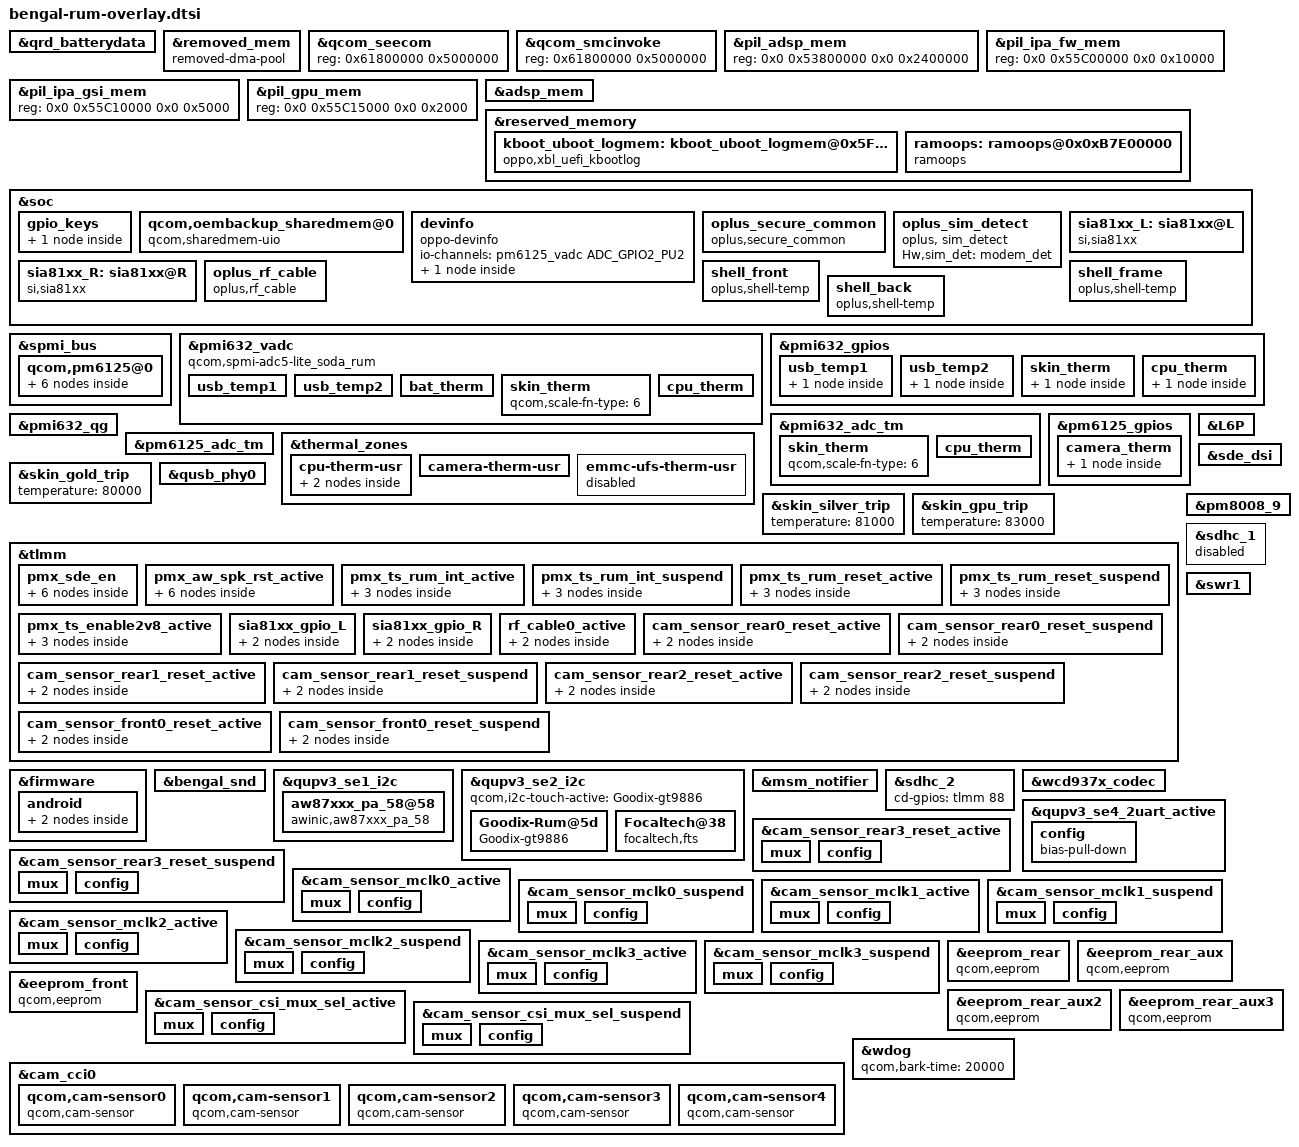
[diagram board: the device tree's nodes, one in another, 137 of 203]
/* *****************
the up part file change like:
delete note  and status = "disabled" to "ok"  add here also, other will meet can't boot issue or compile error issue
**************************/
#include "../../qcom/bengal-qrd.dtsi"
#include "nfc/rum-nfc-sn100t.dtsi"
#include "dsi-panel-oplus20211-s6e8fc1-samsung-fhd-video.dtsi"
#include "fingerprint/bengal-rum-fingerprint-overlay.dtsi"
//bengal.dtsi

&qrd_batterydata {
    /delete-node/ qcom,ATL466271_3300mAh;
    #include "oplus_battery_4000mah_100k_pmi632_TWS_Atl.dtsi"
};
//#ifdef OPLUS_FEATURE_FINGERPRINT
&removed_mem {
	compatible = "removed-dma-pool";
	no-map;
	reg = <0x0 0x60000000 0x0 0x6800000>;
};
&qcom_seecom {
	/delete-property/ reg;
	reg = <0x61800000 0x5000000>;
};
&qcom_smcinvoke {
	/delete-property/ reg;
	reg = <0x61800000 0x5000000>;
};
//#endif /*OPLUS_FEATURE_FINGERPRINT*/

&pil_adsp_mem {
	/delete-property/ reg;
	reg = <0x0 0x53800000 0x0 0x2400000>;
};

&pil_ipa_fw_mem {
	/delete-property/ reg;
	reg = <0x0 0x55C00000 0x0 0x10000>;
};

&pil_ipa_gsi_mem {
	/delete-property/ reg;
	reg = <0x0 0x55C10000 0x0 0x5000>;
};

&pil_gpu_mem {
	/delete-property/ reg;
	reg = <0x0 0x55C15000 0x0 0x2000>;
};

&adsp_mem {
	/delete-property/ reusable;
};

// xbl_uefi_mem address get from boot_images Core.dsc.inc file: PcdEmbeddedFdBaseAddress + SERIAL_BUFFER_OFFSET,0x5FC00000+0x3F7000
// kernel boot log: 0x5FC00000~ 0x5FFF7000
&reserved_memory {
	kboot_uboot_logmem: kboot_uboot_logmem@0x5FC00000 {
		reg = <0x0 0x5FC00000 0x0 0x3FF000>;
		compatible = "oppo,xbl_uefi_kbootlog";
		xbluefi-offset = <0x3F7000>;
		no-map;
	};

	ramoops: ramoops@0x0xB7E00000 {
		compatible = "ramoops";
		reg = <0 0xB7E00000 0 0x00400000>;
		record-size =  <0x40000>; //256x1024
		console-size = <0x40000>;
		ftrace-size =  <0x40000>;
		pmsg-size=         <0x200000>;
		devinfo-size=  <0x01000>;
		ecc-size=          <0x0>;
	};
};
//bengal-qrd.dtsi
&soc {
	gpio_keys {
		vol_up {
			/delete-property/ label;
			label = "volume_down";
			/delete-property/ linux,code;
			linux,code = <KEY_VOLUMEDOWN>;
		};
	};

	//#ifdef FEATURE_OPPO_NV_BACKUP
	//add for creating a shared memory with uio for nv backup and restore
	qcom,oembackup_sharedmem@0 {
		compatible = "qcom,sharedmem-uio";
		reg = <0x0 0x00100000>;
		reg-names = "oembackup";
		qcom,client-id = <0x00000004>;
		qcom,guard-memory;
		qcom,vm-nav-path;
	};
	//#endif /* FEATURE_OPPO_NV_BACKUP */

	devinfo {
		compatible = "oppo-devinfo";

		io-channels= <&pm6125_vadc ADC_GPIO2_PU2>;
		io-channel-names= "vph_pwr_voltage_sub";

		main-sub {
			compatible = "hw-match, main-sub";
			use_pmic_adc;
			adc_ranges = <  0 79
					80 150
					151 849
					850 1050
					1051 1900>;
			aboard-patterns = <1 3 3 1 1 1>;

			/*main board*/
			match-projects = <20011 20211 20212 20213 20214 20215>;
		};
	};
    // #ifdef OPLUS_FEATURE_SECURITY_COMMON
    oplus_secure_common {
        compatible = "oplus,secure_common";
    };
    //#endif /* OPLUS_FEATURE_SECURITY_COMMON */

	//#ifdef OPLUS_FEATRUE_SIM_HOLDER_DETECT
	oplus_sim_detect {
		compatible = "oplus, sim_detect";
		Hw,sim_det = "modem_det";
	};
	//#endif /* OPLUS_FEATRUE_SIM_HOLDER_DETECT */

	//#ifdef OPLUS_ARCH_EXTENDS
	sia81xx_L: sia81xx@L {
			compatible = "si,sia81xx";
			si,sia81xx_type = "sia8109";
			si,sia81xx_reset = <&tlmm 98 0x00>;
			si,sia81xx_owi = <&tlmm 98 0x00>;
			pinctrl-names = "sia81xx_gpio";
			pinctrl-0 = <&sia81xx_gpio_L>;

			si,sia81xx_disable_pin = <1>;

			/* the same value share a same task
			 * valid value range : 0 ~ 7 */
			timer_task_hdl = <0>;

			channel_num = <0>;
			owi_mode = <6>;
			en_x_filter = <1>;
			en_dynamic_updata_vdd = <1>;
			dynamic_updata_vdd_port = <0xb030>;
	};

	sia81xx_R: sia81xx@R {
			compatible = "si,sia81xx";
			si,sia81xx_type = "sia8109";
			si,sia81xx_reset = <&tlmm 107 0x00>;
			si,sia81xx_owi = <&tlmm 107 0x00>;
			pinctrl-names = "sia81xx_gpio";
			pinctrl-0 = <&sia81xx_gpio_R>;

			si,sia81xx_disable_pin = <1>;

			/* the same value share a same task
			 * valid value range : 0 ~ 7 */
			timer_task_hdl = <0>;

			channel_num = <1>;
			owi_mode = <6>;
			en_x_filter = <0>;
			en_dynamic_updata_vdd = <1>;
			dynamic_updata_vdd_port = <0xb030>;
	};
	//#endif /* OPLUS_ARCH_EXTENDS */

	oplus_rf_cable {
		compatible = "oplus,rf_cable";
		interrupt-parent = <&tlmm>;
		rf_cable_support_num = <1>;
		rf,cable0-gpio = <&tlmm 106 0>;
		rf,cable-support-timer = <0>;
		pinctrl-names = "rf_cable_active";
		pinctrl-0 = <&rf_cable0_active>;
	};
	
	
	//#ifdef OPLUS_FEATURE_THERMAL_HORAE
	shell_front {
		compatible = "oplus,shell-temp";
	};

	shell_frame {
		compatible = "oplus,shell-temp";
	};

	shell_back {
		compatible = "oplus,shell-temp";
	};
	//#endif /* OPLUS_FEATURE_THERMAL_HORAE */
};
&spmi_bus {
	qcom,pm6125@0 {
		qcom,power-on@800 {
			qcom,pmicwd;
			qcom,pon_2 {
				qcom,pon-type = <1>;
				qcom,pull-up = <1>;
				linux,code = <KEY_VOLUMEUP>;
			};
		};
		pm6125_vadc: vadc@3100 {
			compatible = "qcom,spmi-adc5_soda_rum";
		};
    };
};
		&pmi632_vadc {
			compatible = "qcom,spmi-adc5-lite_soda_rum";
			pinctrl-0 = <&usb_temp1_default &usb_temp2_default &skin_therm_default &cpu_therm_default>;
			usb_temp1 {
				reg = <ADC_GPIO1_PU2>;
				label = "usb_temp1";
				qcom,ratiometric;
				qcom,hw-settle-time = <200>;
				qcom,pre-scaling = <1 1>;
				qcom,scale-fn-type = <ADC_SCALE_HW_CALIB_DEFAULT>;
			};
			usb_temp2 {
				reg = <ADC_GPIO3_PU2>;
				label = "usb_temp2";
				qcom,ratiometric;
				qcom,hw-settle-time = <200>;
				qcom,pre-scaling = <1 1>;
				qcom,scale-fn-type = <ADC_SCALE_HW_CALIB_DEFAULT>;
			};
			bat_therm {
				reg = <ADC_BAT_THERM_PU1>;
				label = "bat_therm";
				qcom,ratiometric;
				qcom,hw-settle-time = <200>;
				qcom,pre-scaling = <1 1>;
				qcom,lut-index = <3>;
			};
			skin_therm {
				//#ifdef ODM_HQ_EDIT
				qcom,scale-fn-type = <6>;
			};

			//#ifdef ODM_HQ_EDIT
			cpu_therm {
				reg = <ADC_AMUX_THM1_PU2>;
				label = "cpu_therm";
				qcom,ratiometric;
				qcom,hw-settle-time = <200>;
				qcom,pre-scaling = <1 1>;
			};
		};
		&pmi632_gpios {
			usb_temp1 {
				usb_temp1_default: usb_temp1_default {
					pins = "gpio1";
					bias-high-impedance;
				};
			};
			usb_temp2 {
				usb_temp2_default: usb_temp2_default {
					pins = "gpio4";
					bias-high-impedance;
				};
			};
			skin_therm {
				skin_therm_default: skin_therm_default {
					pins = "gpio3";
					bias-high-impedance;
				};
			};
			//#ifdef ODM_HQ_EDIT
			cpu_therm {
				cpu_therm_default: cpu_therm_default {
					pins = "gpio5";
					bias-high-impedance;
				};
			};
		};
		&pmi632_qg {
			io-channels = <&pmi632_vadc ADC_BAT_THERM_PU1>,
				<&pmi632_vadc ADC_PARALLEL_ISENSE>,
				<&pmi632_vadc ADC_BAT_ID_PU2>;
			io-channel-names = "batt-therm",
						"parallel_isense",
						"batt-id";
			qcom,qg-iterm-ma = <450>;
			qcom,s3-entry-ibat-ua = <20000>;
			qcom,s3-exit-ibat-ua = <38000>;
			qcom,vbatt-cutoff-mv = <3390>;
			qcom,fvss-enable;
			qcom,project-index = <1>;// soda = 0; rum = 1; coco = 2
			qcom,enable-qpnp-qg;
		};

&pmi632_adc_tm {
	io-channels = <&pmi632_vadc ADC_GPIO2_PU2>,
			<&pmi632_vadc ADC_AMUX_THM1_PU2>;

	/* Channel nodes */
	skin_therm {
		//#ifdef ODM_HQ_EDIT
		qcom,scale-fn-type = <6>;
		/*#endif*/
	};

	//#ifdef ODM_HQ_EDIT
	cpu_therm {
		reg = <ADC_AMUX_THM1_PU2>;
		qcom,ratiometric;
		qcom,hw-settle-time = <200>;
	};
};

&pm6125_vadc {
	pinctrl-0 = <&camera_therm_default &emmc_therm_default>;
	camera_flash_therm {
		reg = <ADC_GPIO1_PU2>;
		label = "camera_flash_therm";
		qcom,ratiometric;
		qcom,hw-settle-time = <200>;
		qcom,pre-scaling = <1 1>;
		qcom,scale-fn-type = <6>;
	};
};

&pm6125_gpios {
	camera_therm {
		camera_therm_default: camera_therm_default {
			pins = "gpio3";
			bias-high-impedance;
		};
	};
};

&spmi_bus {
	qcom,pm6125@0 {
		pm6125_adc_tm_iio: adc_tm@3400 {
			compatible = "qcom,adc-tm5-iio";
			reg = <0x3400 0x100>;
			#thermal-sensor-cells = <1>;
			#address-cells = <1>;
			#size-cells = <0>;
			io-channels = <&pm6125_vadc ADC_GPIO1_PU2>,
					<&pm6125_vadc ADC_GPIO2_PU2>;

			camera_flash_therm {
				reg = <ADC_GPIO1_PU2>;
				qcom,ratiometric;
				qcom,hw-settle-time = <200>;
			};
		};
	};
};

&pm6125_adc_tm {
	io-channels = <&pm6125_vadc ADC_AMUX_THM1_PU2>,
			<&pm6125_vadc ADC_AMUX_THM2_PU2>,
			<&pm6125_vadc ADC_XO_THERM_PU2>;
};

&thermal_zones {
	//#ifdef ODM_HQ_EDIT
	cpu-therm-usr {
		polling-delay-passive = <0>;
		polling-delay = <0>;
		thermal-governor = "user_space";
		thermal-sensors = <&pmi632_adc_tm ADC_AMUX_THM1_PU2>;
		wake-capable-sensor;
		trips {
			active-config0 {
				temperature = <125000>;
				hysteresis = <1000>;
				type = "passive";
			};
		};
	};
	camera-therm-usr {
		/delete-property/ thermal-sensors;
		thermal-sensors = <&pm6125_adc_tm_iio ADC_GPIO1_PU2>;
	};
	emmc-ufs-therm-usr{
		status = "disabled";
	};
};

/* increase the trigger temp */
&skin_gold_trip {
	temperature = <80000>;
};

&skin_silver_trip {
	temperature = <81000>;
};

&skin_gpu_trip {
	temperature = <83000>;
};

&qusb_phy0 {
	qcom,qusb-phy-init-seq = <0xf8 0x80
				0xb3 0x84
				0x81 0x88
				0xc7 0x8c
				0x30 0x08
				0x79 0x0c
				0x21 0x10
				0x14 0x9c
				0x80 0x04
				0x9f 0x1c
				0x00 0x18>;
	qcom,tune2-efuse-correction = <(-4)>;
};
&tlmm {
	pmx_sde_en {
		sde_en_active: sde_en_active {
			mux {
				pins = "gpio84";
				function = "gpio";
			};

			config {
				pins = "gpio84";
				drive-strength = <8>;
				bias-disable = <0>;
			};
		};

		sde_en_suspend: sde_en_suspend {
			mux {
				pins = "gpio84";
				function = "gpio";
			};

			config {
				pins = "gpio84";
				drive-strength = <2>;
				bias-pull-down;
			};
		};
	};

	pmx_aw_spk_rst_active {
		aw_spk_reset_on: aw_spk_reset_on {
			mux {
				pins = "gpio111";
				function = "gpio";
			};

			config {
				pins = "gpio111";
				drive-strength = <8>;
				bias-pull-up;
			};
		};

		aw_spk_reset_off: aw_spk_reset_off {
			mux {
				pins = "gpio111";
				function = "gpio";
			};

			config {
				pins = "gpio111";
				drive-strength = <2>;
				bias-pull-down;
			};
		};
	};
	
	pmx_ts_rum_int_active {
		ts_rum_int_active: ts_rum_int_active {
			mux {
				pins = "gpio80";
				function = "gpio";
			};

			config {
				pins = "gpio80";
				drive-strength = <8>;
				bias-disable;
			};
		};
	};

	pmx_ts_rum_int_suspend {
		ts_rum_int_suspend: ts_rum_int_suspend {
			mux {
				pins = "gpio80";
				function = "gpio";
			};

			config {
				pins = "gpio80";
				drive-strength = <2>;
				bias-pull-down;
			};
		};
	};

	pmx_ts_rum_reset_active {
		ts_rum_reset_active: ts_rum_reset_active {
			mux {
				pins = "gpio71";
				function = "gpio";
			};

			config {
				pins = "gpio71";
				drive-strength = <8>;
				output-low;
				bias-disable;
			};
		};
	};

	pmx_ts_rum_reset_suspend {
		ts_rum_reset_suspend: ts_rum_reset_suspend {
			mux {
				pins = "gpio71";
				function = "gpio";
			};

			config {
				pins = "gpio71";
				drive-strength = <2>;
				bias-pull-down;
			};
		};
	};

	pmx_ts_enable2v8_active {
		ts_enable2v8_active: ts_enable2v8_active {
			mux {
				pins = "gpio85";
				function = "gpio";
			};

			config {
				pins = "gpio85";
				drive-strength = <8>;
				bias-pull-up;
			};
		};
	};

	//#ifdef OPLUS_ARCH_EXTENDS
	sia81xx_gpio_L: sia81xx_gpio_L {
		mux {
			pins = "gpio98", "gpio98";
			function = "gpio";
		};

		config {
			pins = "gpio98", "gpio98";
			drive-strength = <6>;
			bias-disable;
		};
	};

	sia81xx_gpio_R: sia81xx_gpio_R {
		mux {
			pins = "gpio107", "gpio107";
			function = "gpio";
		};

		config {
			pins = "gpio107", "gpio107";
			drive-strength = <6>;
			bias-disable;
		};
	};
	//#endif /* OPLUS_ARCH_EXTENDS */

	rf_cable0_active: rf_cable0_active {
		mux {
			pins = "gpio106";
			function = "gpio";
		};
		config {
			pins = "gpio106";
			drive-strength = <2>;
			input-enable;
			bias-pull-up;
		};
	};
};

&firmware {
	android {
		fstab {
			vendor {
				/delete-property/ fsmgr_flags;
				fsmgr_flags = "wait,avb";
			};
		};
	};
};

&L6P {
	/delete-property/ regulator-min-microvolt;
	/delete-property/ regulator-max-microvolt;
	regulator-min-microvolt = <2800000>;
	regulator-max-microvolt = <3400000>;
};

&bengal_snd {
	/delete-property/ qcom,wsa-max-devs;
	/delete-property/ qcom,wsa-devs;
	qcom,wsa-max-devs = <0>;
	qcom,wsa-devs = <0>;

	si,sia81xx-max-num = <2>;
	si,sia81xx-aux-devs = <&sia81xx_L>, <&sia81xx_R>;
	si,sia81xx-aux-devs-prefix = "SpkrMonoL", "SpkrMonoR";
};

&qupv3_se1_i2c {
	/delete-node/ nq;

	aw87xxx_pa_58@58{
		compatible = "awinic,aw87xxx_pa_58";
		reg = <0x58>;

		pa-channel = < 0 >;
		/* actflag-gain-array: off music voice fm rcv */
		actflag-gain-array = < 0x00 0x08 0x08 0x08 0x00 >;
		/*actflag-auto-run;*/
		gain-reg-addr = <0x06>;
		monitor-flag = <1>;
		monitor-timer-val = <3000>;
		monitor-timer-count-max = <5>;

		aw87xxx_rst = <&tlmm 111 0x00>;
		pinctrl-names = "spk_reset_on", "spk_reset_off";
		pinctrl-0 = <&aw_spk_reset_on>;
		pinctrl-1 = <&aw_spk_reset_off>;

		status = "okay";
	};
};
&qupv3_se2_i2c {
	/delete-property/ qcom,i2c-touch-active;
	qcom,i2c-touch-active="Goodix-gt9886";
	/delete-node/ synaptics_tcm;

	Goodix-Rum@5d {
		compatible = "Goodix-gt9886";
		reg = <0x5d>;
		chip-name = "GT9886";

		/* Interrupt && Irq-gpio */
		interrupt-parent = <&tlmm>;
		interrupts = <80 0x2002>;

		/* Power Config */
		vdd_2v8-supply = <&L6P>;
		vcc_1v8-supply = <&L9A>;
		//vdd_2v8_volt = <3000000>;

		/* Other HW Resource */
		irq-gpio = <&tlmm 80 0x2002>;
		reset-gpio = <&tlmm 71 0x1>;
		enable2v8_gpio = <&tlmm 85 0x1>;
		pinctrl-names = "default";
		pinctrl-0 = <&ts_enable2v8_active &ts_rum_reset_active &ts_rum_int_active>;

		vid_len = <2>;
		tp_type = <8>;
		// type of tp_dev ,TP-SAMSUNG = 8;
		platform_support_project = <20211 20212 20213 20214 20215>;
		platform_support_project_dir = <20211 20212 20213 20214 20215>;
		platform_support_project_commandline = "mdss_s6e8fc1_samsung_video","mdss_s6e8fc1_samsung_video","mdss_s6e8fc1_samsung_video","mdss_s6e8fc1_samsung_video","mdss_s6e8fc1_samsung_video";
		platform_support_project_external_name = "AAA01", "AAA01", "AAA01", "AAA01", "AA001";

		touchpanel,max-num-support = <10>;
		touchpanel,tx-rx-num = <15 34>;
		touchpanel,panel-coords = <1080 2400>;
		touchpanel,display-coords = <1080 2400>;
		touchpanel,touchmajor-limit = <0 54>;

		/* SW Support Feature Control */
		register-is-16bit;
		black_gesture_support;
		fw_edge_limit_support;
		pressure_report_support;
		charger_pump_support;
		game_switch_support;
		smart_gesture_support;
		fw_update_app_support;
		fingerprint_underscreen_support;
		esd_handle_support;
		new_set_irq_wake_support;
		health_monitor_v2_support;
		irq_need_dev_resume_ok;

		touchpanel,button-type = <4>;
		touchpanel.button-TRx = <0 0>;
	};

	Focaltech@38 {
		compatible = "focaltech,fts";
		reg = <0x38>;
		chip-name = "FT3518";

		/* Interrupt && Irq-gpio */
		interrupt-parent = <&tlmm>;
		interrupts = <80 0x2002>;

		/* Power Config */
		enable2v8_gpio = <&tlmm 85 0x1>;
		vdd_2v8-supply = <&L6P>;
		vcc_1v8-supply = <&L9A>;
		//vdd_2v8_volt = <3000000>;

		/* Other HW Resource */
		irq-gpio = <&tlmm 80 0x2002>;
		reset-gpio = <&tlmm 71 0x1>;
		pinctrl-names = "default";
		pinctrl-0 = <&ts_enable2v8_active &ts_rum_reset_active &ts_rum_int_active>;

		vid_len = <7>;
		tp_type = <8>;
		// type of tp_dev ,TP-SAMSUNG = 8;
		platform_support_project = <20211 20241 20242 20243 20245>;
		platform_support_project_dir = <20211 20241 20241 20241 20241>;
		platform_support_project_commandline = "mdss_am643_samsung_video", "mdss_am643_samsung_video", "mdss_am643_samsung_video", "mdss_am643_samsung_video";
		platform_support_project_external_name = "AA001", "AA001", "AA001", "AA001", "AA001";

		touchpanel,max-num-support = <10>;
		touchpanel,tx-rx-num = <15 34>;
		touchpanel,panel-coords = <1080 2400>;
		touchpanel,display-coords = <1080 2400>;
		touchpanel,touchmajor-limit = <0 54>;

		/* SW Support Feature Control */
		black_gesture_support;
		fw_edge_limit_support;
		pressure_report_support;
		charger_pump_support;
		game_switch_support;
		smart_gesture_support;
		fw_update_app_support;
		fingerprint_underscreen_support;
		esd_handle_support;
		new_set_irq_wake_support;
		health_monitor_v2_support;
		irq_need_dev_resume_ok;

		touchpanel,button-type = <4>;
		touchpanel.button-TRx = <0 0>;
	};
};

&sde_dsi {
	/delete-property/ pinctrl-0;
	/delete-property/ pinctrl-1;
	pinctrl-0 = <&sde_dsi_active &sde_te_active &sde_en_active>;
	pinctrl-1 = <&sde_dsi_suspend &sde_te_suspend &sde_en_suspend>;
	/delete-property/ qcom,dsi-default-panel;
	qcom,dsi-default-panel = <&dsi_s6e8fc1_samsung_video>;
};
&msm_notifier {
	/delete-property/ panel;
	panel = <&dsi_s6e8fc1_samsung_video
		&dsi_s6e8fc1_samsung_video>;
};

&pm8008_9{
	status = "okay";
};

/* #ifdef OPLUS_FEATURE_EMMC_DRIVER */
&sdhc_1 {
       status = "disabled";
};

&sdhc_2 {
       cd-gpios = <&tlmm 88 GPIO_ACTIVE_HIGH>;
       status = "ok";
};
/* #endif */

//bengal-audio-overlay.dtsi
&swr1 {
	/delete-property/ qcom,disable-div2-clk-switch;
};
&wcd937x_codec {
	/delete-property/ qcom,cdc-micbias2-mv;
	qcom,cdc-micbias2-mv = <2700>;
	oplus,mbhc-headset-micbias-alwayon = <1>;
};

&bengal_snd {
	/delete-property/ qcom,wsa-max-devs;
	/delete-property/ qcom,wsa-devs;
	qcom,wsa-max-devs = <0>;
	qcom,wsa-devs = <0>;
};

/*BSP.Kernel.Debug, 2019/06/22, Modify for avoid noise, change from no-pull to bias-pull-down*/
&qupv3_se4_2uart_active {
	config {
	/delete-property/ bias-disable;
	bias-pull-down;
	};
};

//bengal-camera-sensor-qrd.dtsi
&tlmm {
	cam_sensor_rear0_reset_active: cam_sensor_rear0_reset_active {
		mux {
			pins = "gpio18";
			function = "gpio";
		};
		config {
			pins = "gpio18";
			bias-disable; /* No PULL */
			drive-strength = <2>; /* 2 MA */
		};
	};
	cam_sensor_rear0_reset_suspend: cam_sensor_rear0_reset_suspend {
		mux {
			pins = "gpio18";
			function = "gpio";
		};
		config {
			pins = "gpio18";
			bias-pull-down; /* PULL DOWN */
			drive-strength = <2>; /* 2 MA */
			output-low;
		};
	};
	cam_sensor_rear1_reset_active: cam_sensor_rear1_reset_active {
		mux {
			pins = "gpio19";
			function = "gpio";
		};
		config {
			pins = "gpio19";
			bias-disable; /* No PULL */
			drive-strength = <2>; /* 2 MA */
		};
	};
	cam_sensor_rear1_reset_suspend: cam_sensor_rear1_reset_suspend {
		mux {
			pins = "gpio19";
			function = "gpio";
		};
		config {
			pins = "gpio19";
			bias-pull-down; /* PULL DOWN */
			drive-strength = <2>; /* 2 MA */
			output-low;
		};
	};
	cam_sensor_rear2_reset_active: cam_sensor_rear2_reset_active {
		mux {
			pins = "gpio65";
			function = "gpio";
		};
		config {
			pins = "gpio65";
			bias-disable; /* No PULL */
			drive-strength = <2>; /* 2 MA */
		};
	};
	cam_sensor_rear2_reset_suspend: cam_sensor_rear2_reset_suspend {
		mux {
			pins = "gpio65";
			function = "gpio";
		};
		config {
			pins = "gpio65";
			bias-pull-down; /* PULL DOWN */
			drive-strength = <2>; /* 2 MA */
			output-low;
		};
	};
	cam_sensor_front0_reset_active: cam_sensor_front0_reset_active {
		mux {
			pins = "gpio24";
			function = "gpio";
		};
		config {
			pins = "gpio24";
			bias-disable; /* No PULL */
			drive-strength = <2>; /* 2 MA */
		};
	};
	cam_sensor_front0_reset_suspend: cam_sensor_front0_reset_suspend {
		mux {
			pins = "gpio24";
			function = "gpio";
		};
		config {
			pins = "gpio24";
			bias-pull-down; /* PULL DOWN */
			drive-strength = <2>; /* 2 MA */
			output-low;
		};
	};
};

&cam_sensor_rear3_reset_active {
	mux {
		pins = "gpio102";
		function = "gpio";
	};
	config {
		pins = "gpio102";
		bias-disable; /* No PULL */
		drive-strength = <2>; /* 2 MA */
	};
};
&cam_sensor_rear3_reset_suspend {
	mux {
		pins = "gpio102";
		function = "gpio";
	};
	config {
		pins = "gpio102";
		bias-disable; /* No PULL */
		drive-strength = <2>; /* 2 MA */
	};
};
&L6P {
	regulator-min-microvolt = <2800000>;
	regulator-max-microvolt = <3400000>;
};
&cam_sensor_mclk0_active {
	/* MCLK 0*/
	mux {
		pins = "gpio20";
		function = "cam_mclk";
	};

	config {
		pins = "gpio20";
		bias-disable; /* No PULL */
		drive-strength = <4>; /* 2 MA */
	};
};
&cam_sensor_mclk0_suspend {
	/* MCLK 0*/
	mux {
		pins = "gpio20";
		function = "cam_mclk";
	};

	config {
		pins = "gpio20";
		bias-pull-down; /* PULL DOWN */
		drive-strength = <4>; /* 2 MA */
	};
};
&cam_sensor_mclk1_active {
	/* MCLK 1*/
	mux {
		pins = "gpio21";
		function = "cam_mclk";
	};

	config {
		pins = "gpio21";
		bias-disable; /* No PULL */
		drive-strength = <4>; /* 2 MA */
	};
};
&cam_sensor_mclk1_suspend {
	/* MCLK 1*/
	mux {
		pins = "gpio21";
		function = "cam_mclk";
	};

	config {
		pins = "gpio21";
		bias-pull-down; /* PULL DOWN */
		drive-strength = <4>; /* 2 MA */
	};
};
&cam_sensor_mclk2_active {
	/* MCLK 2*/
	mux {
		pins = "gpio27";
		function = "cam_mclk";
	};

	config {
		pins = "gpio27";
		bias-disable; /* No PULL */
		drive-strength = <4>; /* 2 MA */
	};
};

&cam_sensor_mclk2_suspend {
	/* MCLK 2*/
	mux {
		pins = "gpio27";
		function = "cam_mclk";
	};

	config {
		pins = "gpio27";
		bias-pull-down; /* PULL DOWN */
		drive-strength = <4>; /* 2 MA */
	};
};
&cam_sensor_mclk3_active {
	/* MCLK 3*/
	mux {
		pins = "gpio28";
		function = "cam_mclk";
	};

	config {
		pins = "gpio28";
		bias-disable; /* No PULL */
		drive-strength = <4>; /* 2 MA */
	};
};

&cam_sensor_mclk3_suspend {
	/* MCLK 3*/
	mux {
		pins = "gpio28";
		function = "cam_mclk";
	};

	config {
		pins = "gpio28";
		bias-pull-down; /* PULL DOWN */
		drive-strength = <4>; /* 2 MA */
	};
};

&eeprom_rear {
	cell-index = <0>;
	compatible = "qcom,eeprom";
	cam_vio-supply = <&L7P>;
	cam_vana-supply = <&L3P>;
	cam_vdig-supply = <&L1P>;
	cam_vaf-supply = <&L5P>;
	cam_clk-supply = <&gcc_camss_top_gdsc>;
	regulator-names = "cam_vio", "cam_vana", "cam_vdig",
		"cam_clk", "cam_vaf";
	rgltr-cntrl-support;
	pwm-switch;
	rgltr-min-voltage = <1800000 2800000 1200000 0 2800000>;
	rgltr-max-voltage = <1800000 2800000 1200000 0 2800000>;
	rgltr-load-current = <120000 80000 1200000 0 100000>;
	gpio-no-mux = <0>;
	pinctrl-names = "cam_default", "cam_suspend";
	pinctrl-0 = <&cam_sensor_mclk0_active
			&cam_sensor_rear0_reset_active>;
	pinctrl-1 = <&cam_sensor_mclk0_suspend
			&cam_sensor_rear0_reset_suspend>;
	gpios = <&tlmm 20 0>,
		<&tlmm 18 0>;
	gpio-reset = <1>;
	gpio-req-tbl-num = <0 1>;
	gpio-req-tbl-flags = <1 0>;
	gpio-req-tbl-label = "CAMIF_MCLK0",
				"CAM_RESET0";
	sensor-mode = <0>;
	cci-master = <0>;
	status = "ok";
	clocks = <&gcc GCC_CAMSS_MCLK0_CLK>;
	clock-names = "cam_clk";
	clock-cntl-level = "turbo";
	clock-rates = <24000000>;
};

&eeprom_rear_aux {
	cell-index = <1>;
	compatible = "qcom,eeprom";
	cam_vio-supply = <&L7P>;
	cam_vana-supply = <&L4P>;
	cam_vdig-supply = <&L2P>;
	//cam_vaf-supply = <&L5P>;
	cam_clk-supply = <&gcc_camss_top_gdsc>;
	regulator-names = "cam_vio", "cam_vana", "cam_vdig",
		"cam_clk";
	rgltr-cntrl-support;
	pwm-switch;
	rgltr-min-voltage = <1800000 2800000 1200000 0>;
	rgltr-max-voltage = <1800000 2800000 1200000 0>;
	rgltr-load-current = <120000 80000 1200000 0>;
	gpio-no-mux = <0>;
	pinctrl-names = "cam_default", "cam_suspend";
	pinctrl-0 = <&cam_sensor_mclk1_active
			&cam_sensor_rear1_reset_active>;
	pinctrl-1 = <&cam_sensor_mclk1_suspend
			&cam_sensor_rear1_reset_suspend>;
	gpios = <&tlmm 21 0>,
		<&tlmm 19 0>;
	gpio-reset = <1>;
	gpio-req-tbl-num = <0 1>;
	gpio-req-tbl-flags = <1 0>;
	gpio-req-tbl-label = "CAMIF_MCLK1",
				"CAM_RESET1";
	sensor-mode = <0>;
	cci-master = <1>;
	status = "ok";
	clocks = <&gcc GCC_CAMSS_MCLK1_CLK>;
	clock-names = "cam_clk";
	clock-cntl-level = "turbo";
	clock-rates = <24000000>;
};

&eeprom_front {
	cell-index = <2>;
	compatible = "qcom,eeprom";
	cam_vio-supply = <&L7P>;
	cam_vana-supply = <&L4P>;
	cam_vdig-supply = <&L2P>;
	cam_clk-supply = <&gcc_camss_top_gdsc>;
	regulator-names = "cam_vio", "cam_vana", "cam_vdig",
		"cam_clk";
	rgltr-cntrl-support;
	pwm-switch;
	rgltr-min-voltage = <1800000 2800000 1050000 0>;
	rgltr-max-voltage = <1800000 2800000 1200000 0>;
	rgltr-load-current = <0 80000 1200000 0>;
	gpio-no-mux = <0>;
	pinctrl-names = "cam_default", "cam_suspend";
	pinctrl-0 = <&cam_sensor_mclk2_active
			&cam_sensor_front0_reset_active>;
	pinctrl-1 = <&cam_sensor_mclk2_suspend
			&cam_sensor_front0_reset_suspend>;
	gpios = <&tlmm 27 0>,
		<&tlmm 24 0>;
	gpio-reset = <1>;
	gpio-req-tbl-num = <0 1>;
	gpio-req-tbl-flags = <1 0>;
	gpio-req-tbl-label = "CAMIF_MCLK2",
				"CAM_RESET2";
	sensor-mode = <0>;
	cci-master = <1>;
	status = "ok";
	clocks = <&gcc GCC_CAMSS_MCLK2_CLK>;
	clock-names = "cam_clk";
	clock-cntl-level = "turbo";
	clock-rates = <24000000>;
};

&eeprom_rear_aux2 {
	cell-index = <3>;
	compatible = "qcom,eeprom";
	cam_vio-supply = <&L7P>;
	cam_vana-supply = <&L4P>;
	//cam_vdig-supply = <&L1P>;
	cam_clk-supply = <&gcc_camss_top_gdsc>;
	regulator-names = "cam_vio", "cam_vana",
		"cam_clk";
	rgltr-cntrl-support;
	pwm-switch;
	rgltr-min-voltage = <1800000 2800000 0>;
	rgltr-max-voltage = <1800000 2800000 0>;
	rgltr-load-current = <120000 80000 0>;
	gpio-no-mux = <0>;
	pinctrl-names = "cam_default", "cam_suspend";
	pinctrl-0 = <&cam_sensor_mclk3_active
			&cam_sensor_rear2_reset_active>;
	pinctrl-1 = <&cam_sensor_mclk3_suspend
			&cam_sensor_rear2_reset_suspend>;
	gpios = <&tlmm 28 0>,
		<&tlmm 65 0>;
	gpio-reset = <1>;
	gpio-req-tbl-num = <0 1>;
		gpio-req-tbl-flags = <1 0>;
	gpio-req-tbl-label = "CAMIF_MCLK3",
				"CAM_RESET3";
	sensor-mode = <0>;
	cci-master = <1>;
	status = "ok";
	clocks = <&gcc GCC_CAMSS_MCLK3_CLK>;
	clock-names = "cam_clk";
	clock-cntl-level = "turbo";
	clock-rates = <24000000>;
};

&eeprom_rear_aux3 {
	cell-index = <4>;
	compatible = "qcom,eeprom";
	cam_vio-supply = <&L7P>;
	cam_vana-supply = <&L4P>;
	//cam_vdig-supply = <&L1P>;
	cam_clk-supply = <&gcc_camss_top_gdsc>;
	regulator-names = "cam_vio", "cam_vana",
		"cam_clk";
	rgltr-cntrl-support;
	pwm-switch;
	rgltr-min-voltage = <1800000 2800000 0>;
	rgltr-max-voltage = <1800000 2800000 0>;
	rgltr-load-current = <120000 80000 0>;
	gpio-no-mux = <0>;
	pinctrl-names = "cam_default", "cam_suspend";
	pinctrl-0 = <&cam_sensor_mclk3_active
			&cam_sensor_rear3_reset_active>;
	pinctrl-1 = <&cam_sensor_mclk3_suspend
			&cam_sensor_rear3_reset_suspend>;
	gpios = <&tlmm 28 0>,
		<&tlmm 102 0>;
	gpio-reset = <1>;
	gpio-req-tbl-num = <0 1>;
	gpio-req-tbl-flags = <1 0>;
	gpio-req-tbl-label = "CAMIF_MCLK3",
				"CAM_RESET4";
	sensor-mode = <0>;
	cci-master = <0>;
	status = "ok";
	clocks = <&gcc GCC_CAMSS_MCLK3_CLK>;
	clock-names = "cam_clk";
	clock-cntl-level = "turbo";
	clock-rates = <24000000>;
};

&cam_sensor_csi_mux_sel_active {
	/*CSIMUX_SEL*/
	mux {
		pins = "gpio108";
		function = "gpio";
	};

	config {
		pins = "gpio108";
		bias-disable; /* No PULL */
		drive-strength = <2>; /* 2 MA */
	};
};

&cam_sensor_csi_mux_sel_suspend {
	/* CSIMUX_SEL */
	mux {
		pins = "gpio108";
		function = "gpio";
	};

	config {
		pins = "gpio108";
		bias-pull-down; /* PULL DOWN */
		drive-strength = <2>; /* 2 MA */
		output-low;
	};
};

&cam_cci0 {
	qcom,cam-sensor0 {
		cell-index = <0>;
		compatible = "qcom,cam-sensor";
		csiphy-sd-index = <0>;
		sensor-position-roll = <90>;
		sensor-position-pitch = <0>;
		sensor-position-yaw = <180>;
		actuator-src = <&actuator_rear>;
		led-flash-src = <&led_flash_rear>;
		eeprom-src = <&eeprom_rear>;
		cam_vio-supply = <&L7P>;
		cam_vana-supply = <&L3P>;
		cam_vdig-supply = <&L1P>;
		cam_vaf-supply = <&L5P>;
		cam_clk-supply = <&gcc_camss_top_gdsc>;
		regulator-names = "cam_vio", "cam_vana", "cam_vdig",
			"cam_clk", "cam_vaf";
		rgltr-cntrl-support;
		pwm-switch;
		rgltr-min-voltage = <1800000 2800000 1200000 0 2800000>;
		rgltr-max-voltage = <1800000 2800000 1200000 0 2800000>;
		rgltr-load-current = <120000 80000 1200000 0 100000>;
		gpio-no-mux = <0>;
		pinctrl-names = "cam_default", "cam_suspend";
		pinctrl-0 = <&cam_sensor_mclk0_active
				&cam_sensor_rear0_reset_active>;
		pinctrl-1 = <&cam_sensor_mclk0_suspend
				&cam_sensor_rear0_reset_suspend>;
		gpios = <&tlmm 20 0>,
			<&tlmm 18 0>;
		gpio-reset = <1>;
		gpio-req-tbl-num = <0 1>;
		gpio-req-tbl-flags = <1 0>;
		gpio-req-tbl-label = "CAMIF_MCLK0",
					"CAM_RESET0";
		sensor-mode = <0>;
		cci-master = <0>;
		status = "ok";
		clocks = <&gcc GCC_CAMSS_MCLK0_CLK>;
		clock-names = "cam_clk";
		clock-cntl-level = "turbo";
		clock-rates = <24000000>;
	};

	qcom,cam-sensor1 {
		cell-index = <1>;
		compatible = "qcom,cam-sensor";
		csiphy-sd-index = <1>;
		sensor-position-roll = <90>;
		sensor-position-pitch = <0>;
		sensor-position-yaw = <180>;
		//actuator-src = <&actuator_rear_aux>;
		//led-flash-src = <&led_flash_rear_aux>;
		eeprom-src = <&eeprom_rear_aux>;
		cam_vio-supply = <&L7P>;
		cam_vana-supply = <&L4P>;
		cam_vdig-supply = <&L2P>;
		//cam_vaf-supply = <&L5P>;
		cam_clk-supply = <&gcc_camss_top_gdsc>;
		regulator-names = "cam_vio", "cam_vana", "cam_vdig",
			"cam_clk";
		rgltr-cntrl-support;
		pwm-switch;
		rgltr-min-voltage = <1800000 2800000 1200000 0>;
		rgltr-max-voltage = <1800000 2800000 1200000 0>;
		rgltr-load-current = <120000 80000 1200000 0>;
		gpio-no-mux = <0>;
		pinctrl-names = "cam_default", "cam_suspend";
		pinctrl-0 = <&cam_sensor_mclk1_active
				&cam_sensor_rear1_reset_active>;
		pinctrl-1 = <&cam_sensor_mclk1_suspend
				&cam_sensor_rear1_reset_suspend>;
		gpios = <&tlmm 21 0>,
			<&tlmm 19 0>;
		gpio-reset = <1>;
		gpio-req-tbl-num = <0 1>;
		gpio-req-tbl-flags = <1 0>;
		gpio-req-tbl-label = "CAMIF_MCLK1",
					"CAM_RESET1";
		sensor-mode = <0>;
		cci-master = <1>;
		status = "ok";
		clocks = <&gcc GCC_CAMSS_MCLK1_CLK>;
		clock-names = "cam_clk";
		clock-cntl-level = "turbo";
		clock-rates = <24000000>;
	};

	qcom,cam-sensor2 {
		cell-index = <2>;
		compatible = "qcom,cam-sensor";
		csiphy-sd-index = <2>;
		sensor-position-roll = <270>;
		sensor-position-pitch = <0>;
		sensor-position-yaw = <0>;
		eeprom-src = <&eeprom_front>;
		cam_vio-supply = <&L7P>;
		cam_vana-supply = <&L4P>;
		cam_vdig-supply = <&L2P>;
		cam_clk-supply = <&gcc_camss_top_gdsc>;
		regulator-names = "cam_vio", "cam_vana", "cam_vdig",
			"cam_clk";
		rgltr-cntrl-support;
		pwm-switch;
		rgltr-min-voltage = <1800000 2800000 1050000 0>;
		rgltr-max-voltage = <1800000 2800000 1200000 0>;
		rgltr-load-current = <0 80000 1200000 0>;
		gpio-no-mux = <0>;
		pinctrl-names = "cam_default", "cam_suspend";
		pinctrl-0 = <&cam_sensor_mclk2_active
				&cam_sensor_front0_reset_active>;
		pinctrl-1 = <&cam_sensor_mclk2_suspend
				&cam_sensor_front0_reset_suspend>;
		gpios = <&tlmm 27 0>,
			<&tlmm 24 0>;
		gpio-reset = <1>;
		gpio-req-tbl-num = <0 1>;
		gpio-req-tbl-flags = <1 0>;
		gpio-req-tbl-label = "CAMIF_MCLK2",
					"CAM_RESET2";
		sensor-mode = <0>;
		cci-master = <1>;
		status = "ok";
		clocks = <&gcc GCC_CAMSS_MCLK2_CLK>;
		clock-names = "cam_clk";
		clock-cntl-level = "turbo";
		clock-rates = <24000000>;
	};

	/*Rear Aux2 horizontal 2M*/
	qcom,cam-sensor3 {
		cell-index = <3>;
		compatible = "qcom,cam-sensor";
		csiphy-sd-index = <1>;
		sensor-position-roll = <90>;
		sensor-position-pitch = <0>;
		sensor-position-yaw = <180>;
		//led-flash-src = <&led_flash_rear_aux2>;
		eeprom-src = <&eeprom_rear_aux2>;
		cam_vio-supply = <&L7P>;
		cam_vana-supply = <&L4P>;
		//cam_vdig-supply = <&L1P>;
		cam_clk-supply = <&gcc_camss_top_gdsc>;
		regulator-names = "cam_vio", "cam_vana",
			"cam_clk";
		rgltr-cntrl-support;
		pwm-switch;
		rgltr-min-voltage = <1800000 2800000 0>;
		rgltr-max-voltage = <1800000 2800000 0>;
		rgltr-load-current = <120000 80000 0>;
		gpio-no-mux = <0>;
		pinctrl-names = "cam_default", "cam_suspend";
		pinctrl-0 = <&cam_sensor_mclk3_active
				&cam_sensor_rear2_reset_active
				&cam_sensor_csi_mux_sel_active>;
		pinctrl-1 = <&cam_sensor_mclk3_suspend
				&cam_sensor_rear2_reset_suspend
				&cam_sensor_csi_mux_sel_suspend>;
		gpios = <&tlmm 28 0>,
			<&tlmm 65 0>,
			<&tlmm 108 0>;
		gpio-reset = <1>;
		gpio-custom1 = <2>;
		gpio-req-tbl-num = <0 1>;
		gpio-req-tbl-flags = <1 0>;
		gpio-req-tbl-label = "CAMIF_MCLK3",
					"CAM_RESET3",
					"CAM_CSIMUX_SEL1";
		sensor-mode = <0>;
		cci-master = <1>;
		status = "ok";
		clocks = <&gcc GCC_CAMSS_MCLK3_CLK>;
		clock-names = "cam_clk";
		clock-cntl-level = "turbo";
		clock-rates = <24000000>;
	};

	/*Rear Aux2 Vertical 2M*/
	qcom,cam-sensor4 {
		cell-index = <4>;
		compatible = "qcom,cam-sensor";
		csiphy-sd-index = <1>;
		sensor-position-roll = <90>;
		sensor-position-pitch = <0>;
		sensor-position-yaw = <180>;
		//led-flash-src = <&led_flash_rear_aux2>;
		eeprom-src = <&eeprom_rear_aux3>;
		cam_vio-supply = <&L7P>;
		cam_vana-supply = <&L4P>;
		//cam_vdig-supply = <&L1P>;
		cam_clk-supply = <&gcc_camss_top_gdsc>;
		regulator-names = "cam_vio", "cam_vana",
			"cam_clk";
		rgltr-cntrl-support;
		pwm-switch;
		rgltr-min-voltage = <1800000 2800000 0>;
		rgltr-max-voltage = <1800000 2800000 0>;
		rgltr-load-current = <120000 80000 0>;
		gpio-no-mux = <0>;
		pinctrl-names = "cam_default", "cam_suspend";
		pinctrl-0 = <&cam_sensor_mclk3_active
				&cam_sensor_rear3_reset_active
				&cam_sensor_csi_mux_sel_active>;
		pinctrl-1 = <&cam_sensor_mclk3_suspend
				&cam_sensor_rear3_reset_suspend
				&cam_sensor_csi_mux_sel_suspend>;
		gpios = <&tlmm 28 0>,
			<&tlmm 102 0>,
			<&tlmm 108 0>;
		gpio-reset = <1>;
		gpio-custom1 = <2>;
		gpio-req-tbl-num = <0 1>;
		gpio-req-tbl-flags = <1 0>;
		gpio-req-tbl-label = "CAMIF_MCLK3",
					"CAM_RESET4",
					"CAM_CSIMUX_SEL1";
		sensor-mode = <0>;
		cci-master = <0>;
		status = "ok";
		clocks = <&gcc GCC_CAMSS_MCLK3_CLK>;
		clock-names = "cam_clk";
		clock-cntl-level = "turbo";
		clock-rates = <24000000>;
	};
};

//modify bark time to 20s
&wdog {
	/delete-property/ qcom,bark-time;
	qcom,bark-time = <20000>;
};
